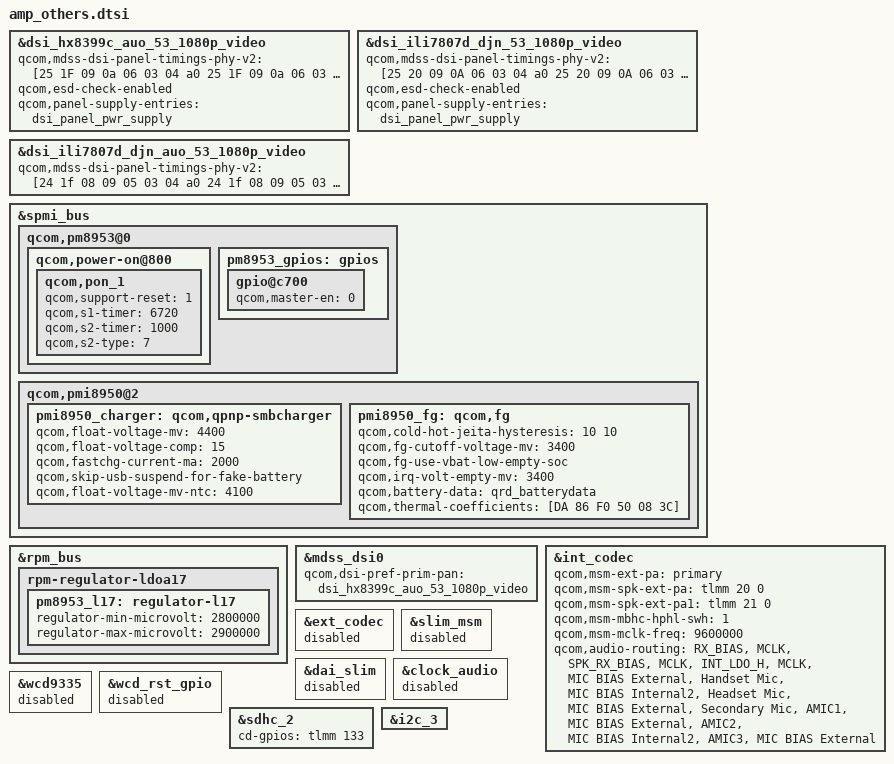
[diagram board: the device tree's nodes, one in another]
// "&blabla_bla {}"

#include "dsi-panel-hx8399c-auo-53-1080p-video.dtsi"
#include "dsi-panel-ili7807d-djn-53-1080p-video.dtsi"
#include "dsi-panel-ili7807d-djn-auo-53-1080p-video.dtsi"

&dsi_hx8399c_auo_53_1080p_video {
	qcom,mdss-dsi-panel-timings-phy-v2  = [25 1F 09 0a 06 03 04 a0
		25 1F 09 0a 06 03 04 a0
		25 1F 09 0a 06 03 04 a0
		25 1F 09 0a 06 03 04 a0
	        25 1E 08 0a 06 03 04 a0];
};

&dsi_ili7807d_djn_53_1080p_video {
	qcom,mdss-dsi-panel-timings-phy-v2  = [25 20 09 0A 06 03 04 a0
		25 20 09 0A 06 03 04 a0
		25 20 09 0A 06 03 04 a0
		25 20 09 0A 06 03 04 a0
	        25 1E 09 0A 06 03 04 a0];
};

&dsi_ili7807d_djn_auo_53_1080p_video {
	qcom,mdss-dsi-panel-timings-phy-v2  = [24 1f 08 09 05 03 04 a0
		24 1f 08 09 05 03 04 a0
		24 1f 08 09 05 03 04 a0
		24 1f 08 09 05 03 04 a0
	        24 1b 08 08 05 03 04 a0];
};

/delete-node/ &pm8953_typec;

&spmi_bus {

	qcom,pm8953@0 {

		qcom,power-on@800 {

			qcom,pon_1 {
				qcom,support-reset = <1>;
				qcom,s1-timer = <6720>;
				qcom,s2-timer = <1000>;
				qcom,s2-type = <7>;
			};
		};

		pm8953_gpios: gpios {

			gpio@c700 {
				/delete-property/ status;
				qcom,master-en = <0>;
			};
		};
	};

	qcom,pmi8950@2 {

		pmi8950_charger: qcom,qpnp-smbcharger {
			qcom,float-voltage-mv = <4400>;
			qcom,float-voltage-comp = <15>;
			qcom,fastchg-current-ma = <2000>;
			/delete-property/ qcom,fastchg-current-comp; 
			qcom,skip-usb-suspend-for-fake-battery;
			qcom,thermal-mitigation = <2000 2000 2000 2000 2000 2000 2000>;
			/delete-property/ qcom,parallel-usb-min-current-ma;
			/delete-property/ qcom,parallel-usb-9v-min-current-ma;
			/delete-property/ qcom,parallel-allowed-lowering-ma;
			qcom,float-voltage-mv-ntc = <4100>;
			/delete-property/ qcom,external-typec;
			/delete-property/ qcom,typec-psy-name;
			/delete-property/ qcom,thermal-mitigation;
		};

		pmi8950_fg: qcom,fg {
			qcom,cold-bat-decidegc = <(-300)>;
			qcom,cool-bat-decidegc = <(-200)>;
			qcom,hot-bat-decidegc = <650>;
			qcom,warm-bat-decidegc = <610>;
			qcom,cold-hot-jeita-hysteresis = <10 10>;
			qcom,fg-cutoff-voltage-mv = <3400>;
			qcom,fg-use-vbat-low-empty-soc;
            		qcom,irq-volt-empty-mv = <3400>;
			qcom,battery-data = <&qrd_batterydata>;
			/delete-property/ qcom,cold-bat-decidegc;
			/delete-property/ qcom,cool-bat-decidegc;
			/delete-property/ qcom,hot-bat-decidegc;
			/delete-property/ qcom,warm-bat-decidegc;
			/delete-property/ qcom,fg-therm-delay-us;
			qcom,thermal-coefficients = [DA 86 F0 50 08 3C];
		};
	};
};

&rpm_bus {

	rpm-regulator-ldoa17 {

		pm8953_l17: regulator-l17 {
			regulator-min-microvolt = <2800000>;
			regulator-max-microvolt = <2900000>;
		};
	};
};

&mdss_dsi0 {
	qcom,dsi-pref-prim-pan = <&dsi_hx8399c_auo_53_1080p_video>;
};

&dsi_hx8399c_auo_53_1080p_video {
	qcom,esd-check-enabled;
	qcom,panel-supply-entries = <&dsi_panel_pwr_supply>;
};

&dsi_ili7807d_djn_53_1080p_video {
	qcom,esd-check-enabled;
	qcom,panel-supply-entries = <&dsi_panel_pwr_supply>;
};

/delete-node/ &dsi_r69006_1080p_cmd;

/delete-node/ &dsi_r69006_1080p_video;

&int_codec {
	status = "ok";
	qcom,msm-ext-pa = "primary";
	/delete-property/ qcom,cdc-us-euro-gpios;
	qcom,msm-spk-ext-pa = <&tlmm 20 0>;
	qcom,msm-spk-ext-pa1 = <&tlmm 21 0>;
	qcom,msm-mbhc-hphl-swh = <1>;
	/delete-property/ qcom,msm-micbias1-ext-cap;
	qcom,msm-mclk-freq = <9600000>;
	qcom,audio-routing =
			"RX_BIAS", "MCLK",
			"SPK_RX_BIAS", "MCLK",
			"INT_LDO_H", "MCLK",
			"MIC BIAS External", "Handset Mic",
			"MIC BIAS Internal2", "Headset Mic",
			"MIC BIAS External", "Secondary Mic",
			"AMIC1", "MIC BIAS External",
			"AMIC2", "MIC BIAS Internal2",
			"AMIC3", "MIC BIAS External";
};
/*
&pm8953_diangu_dig {
	status = "ok";
};

&pm8953_diangu_analog {
	status = "ok";
};
*/
&ext_codec {
	status = "disabled";
};

&slim_msm {
	status = "disabled";
};

&dai_slim {
	status = "disabled";
};

&clock_audio {
	status = "disabled";
};

&wcd9335 {
	status = "disabled";
};

&wcd_rst_gpio {
	status = "disabled";
};

&sdhc_2 {
	cd-gpios = <&tlmm 133 0x0>;
};

&i2c_3 {
	status = "ok";
};

// /delete-node/ &flash_led;

// /delete-node/ &led_flash0;
